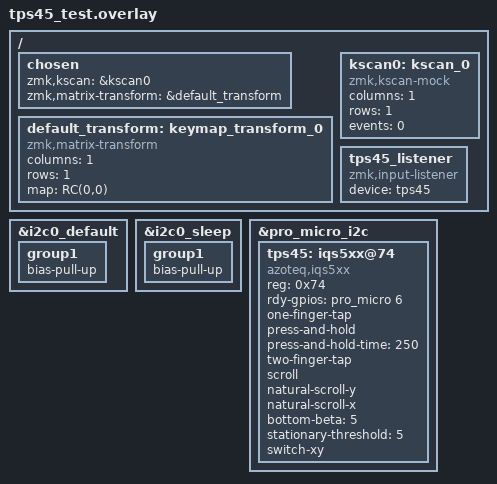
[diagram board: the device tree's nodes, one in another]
#include <dt-bindings/zmk/matrix_transform.h>

/ {
    chosen {
        zmk,kscan = &kscan0;
        zmk,matrix-transform = &default_transform;
    };

    default_transform: keymap_transform_0 {
        compatible = "zmk,matrix-transform";
        columns = <1>;
        rows = <1>;
        map = <RC(0,0)>;
    };

    kscan0: kscan_0 {
        compatible = "zmk,kscan-mock";
        columns = <1>;
        rows = <1>;
        events = <0>;
    };

    tps45_listener: tps45_listener {
        compatible = "zmk,input-listener";
        device = <&tps45>;
    };
};

&i2c0_default {
    group1 {
        bias-pull-up;
    };
};

&i2c0_sleep {
    group1 {
        bias-pull-up;
    };
};

&pro_micro_i2c {
    status = "okay";

    tps45: iqs5xx@74 {
        status = "okay";
        compatible = "azoteq,iqs5xx";
        reg = <0x74>;

        rdy-gpios = <&pro_micro 6 GPIO_ACTIVE_HIGH>;

        one-finger-tap;
        press-and-hold;
        press-and-hold-time = <250>;
        two-finger-tap;

        scroll;
        natural-scroll-y;
        natural-scroll-x;

        bottom-beta = <5>;
        stationary-threshold = <5>;

        switch-xy;
    };
};
